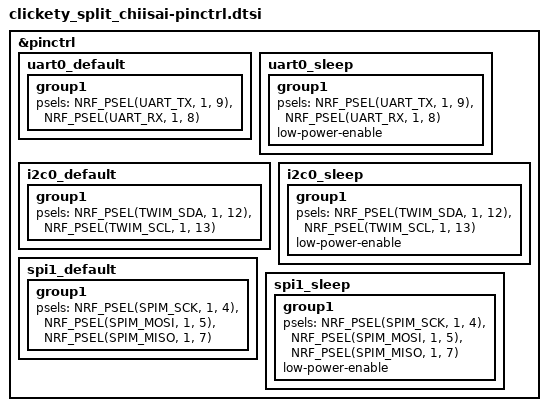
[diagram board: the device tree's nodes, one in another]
/*
 * Copyright (c) 2025 Clickety Split Ltd.
 * SPDX-License-Identifier: MIT
 */

&pinctrl {
    uart0_default: uart0_default {
        group1 {
            psels = <NRF_PSEL(UART_TX, 1, 9)>,
                <NRF_PSEL(UART_RX, 1, 8)>;
        };
    };

    uart0_sleep: uart0_sleep {
        group1 {
            psels = <NRF_PSEL(UART_TX, 1, 9)>,
                <NRF_PSEL(UART_RX, 1, 8)>;
            low-power-enable;
        };
    };

    i2c0_default: i2c0_default {
        group1 {
            psels = <NRF_PSEL(TWIM_SDA, 1, 12)>,
                <NRF_PSEL(TWIM_SCL, 1, 13)>;
        };
    };

    i2c0_sleep: i2c0_sleep {
        group1 {
            psels = <NRF_PSEL(TWIM_SDA, 1, 12)>,
                <NRF_PSEL(TWIM_SCL, 1, 13)>;
            low-power-enable;
        };
    };

    spi1_default: spi1_default {
        group1 {
            psels = <NRF_PSEL(SPIM_SCK, 1, 4)>,
                <NRF_PSEL(SPIM_MOSI, 1, 5)>,
                <NRF_PSEL(SPIM_MISO, 1, 7)>;
        };
    };

    spi1_sleep: spi1_sleep {
        group1 {
            psels = <NRF_PSEL(SPIM_SCK, 1, 4)>,
                <NRF_PSEL(SPIM_MOSI, 1, 5)>,
                <NRF_PSEL(SPIM_MISO, 1, 7)>;
            low-power-enable;
        };
    };
};
